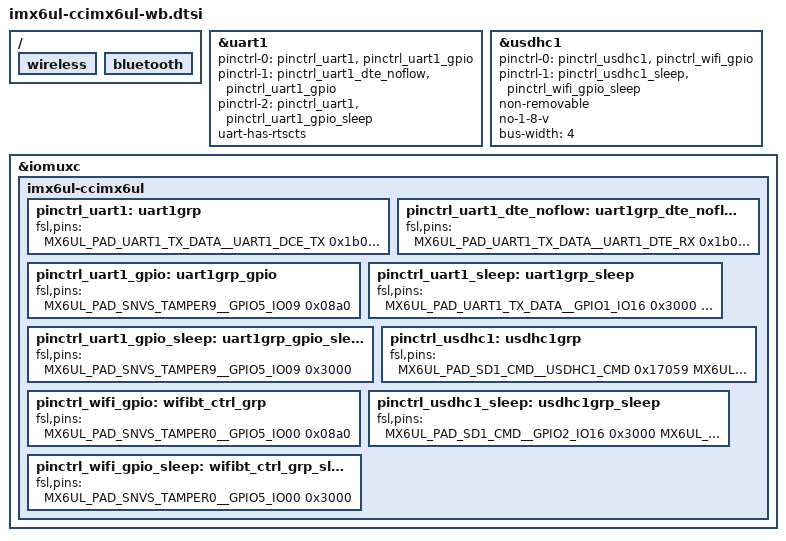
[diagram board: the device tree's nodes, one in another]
/*
 * Copyright 2016, 2017 Digi International, Inc.
 *
 * The code contained herein is licensed under the GNU General Public
 * License. You may obtain a copy of the GNU General Public License
 * Version 2 or later at the following locations:
 *
 * http://www.opensource.org/licenses/gpl-license.html
 * http://www.gnu.org/copyleft/gpl.html
 */

/* ConnectCore 6UL (common) */
#include "imx6ul-ccimx6ul.dtsi"

/ {
	wireless {
		/* U-Boot will fill in the MAC address here */
	};

	bluetooth {
		/* U-Boot will fill in the MAC address here */
	};
};

/* UART1 (Bluetooth) */
&uart1 {
	pinctrl-names = "default", "dte_noflow", "sleep";
	pinctrl-0 = <&pinctrl_uart1 &pinctrl_uart1_gpio>;
	pinctrl-1 = <&pinctrl_uart1_dte_noflow &pinctrl_uart1_gpio>;
	pinctrl-2 = <&pinctrl_uart1 &pinctrl_uart1_gpio_sleep>;
	uart-has-rtscts;
	/*
	 * NOTE: The default configuration for CC6UL SOM hardware vesion 4
	 * onwards is:
	 *	- pinctrl-0
	 *	- HW flow control enabled (uart-has-rtscts)
	 *	- DCE mode (default)
	 * For SOMs with hardware version < 4 the UART driver changes the
	 * configuration of UART1 to:
	 *	- pinctrl-1
	 *	- no HW flow control
	 *	- DTE mode
	 */
	status = "okay";
};

/* USDHC1 (Wireless) */
&usdhc1 {
	pinctrl-names = "default", "sleep";
	pinctrl-0 = <&pinctrl_usdhc1 &pinctrl_wifi_gpio>;
	pinctrl-1 = <&pinctrl_usdhc1_sleep &pinctrl_wifi_gpio_sleep>;
	non-removable;
	no-1-8-v;
	bus-width = <4>;
	status = "okay";
};

&iomuxc {
	imx6ul-ccimx6ul {
		/* This iomux (pinctrl_uart1) does not work for SOM v3 or older */
		pinctrl_uart1: uart1grp {
			fsl,pins = <
				MX6UL_PAD_UART1_TX_DATA__UART1_DCE_TX	0x1b0b1
				MX6UL_PAD_UART1_RX_DATA__UART1_DCE_RX	0x1b0b1
				MX6UL_PAD_UART1_RTS_B__UART1_DCE_RTS	0x1b0b1
				MX6UL_PAD_UART1_CTS_B__UART1_DCE_CTS	0x1b0b1
			>;
		};

		pinctrl_uart1_dte_noflow: uart1grp_dte_noflow {
			fsl,pins = <
				MX6UL_PAD_UART1_TX_DATA__UART1_DTE_RX	0x1b0b1
				MX6UL_PAD_UART1_RX_DATA__UART1_DTE_TX	0x1b0b1
				MX6UL_PAD_UART1_RTS_B__GPIO1_IO19	0x1b0b1
				MX6UL_PAD_UART1_CTS_B__GPIO1_IO18	0x1b0b1
			>;
		};

		pinctrl_uart1_gpio: uart1grp_gpio {
			fsl,pins = <
				/* BT_EN. Configure as open-drain */
				MX6UL_PAD_SNVS_TAMPER9__GPIO5_IO09	0x08a0
			>;
		};

		pinctrl_uart1_sleep: uart1grp_sleep {
			fsl,pins = <
				MX6UL_PAD_UART1_TX_DATA__GPIO1_IO16	0x3000
				MX6UL_PAD_UART1_RX_DATA__GPIO1_IO17	0x3000
				MX6UL_PAD_UART1_RTS_B__GPIO1_IO19	0x3000
				MX6UL_PAD_UART1_CTS_B__GPIO1_IO18	0x3000
			>;
		};

		pinctrl_uart1_gpio_sleep: uart1grp_gpio_sleep {
			fsl,pins = <
				/* BT_EN */
				MX6UL_PAD_SNVS_TAMPER9__GPIO5_IO09	0x3000
			>;
		};

		pinctrl_usdhc1: usdhc1grp {
			fsl,pins = <
				MX6UL_PAD_SD1_CMD__USDHC1_CMD		0x17059
				MX6UL_PAD_SD1_CLK__USDHC1_CLK		0x17051
				MX6UL_PAD_SD1_DATA0__USDHC1_DATA0	0x17059
				MX6UL_PAD_SD1_DATA1__USDHC1_DATA1	0x17059
				MX6UL_PAD_SD1_DATA2__USDHC1_DATA2	0x17059
				MX6UL_PAD_SD1_DATA3__USDHC1_DATA3	0x17059
			>;
		};

		pinctrl_wifi_gpio: wifibt_ctrl_grp {
			fsl,pins = <
				/* WL_EN. Configure as open-drain */
				MX6UL_PAD_SNVS_TAMPER0__GPIO5_IO00	0x08a0
			>;
		};

		pinctrl_usdhc1_sleep: usdhc1grp_sleep {
			fsl,pins = <
				MX6UL_PAD_SD1_CMD__GPIO2_IO16		0x3000
				MX6UL_PAD_SD1_CLK__GPIO2_IO17		0x3000
				MX6UL_PAD_SD1_DATA0__GPIO2_IO18		0x3000
				MX6UL_PAD_SD1_DATA1__GPIO2_IO19		0x3000
				MX6UL_PAD_SD1_DATA2__GPIO2_IO20		0x3000
				MX6UL_PAD_SD1_DATA3__GPIO2_IO21		0x3000
			>;
		};

		pinctrl_wifi_gpio_sleep: wifibt_ctrl_grp_sleep {
			fsl,pins = <
				MX6UL_PAD_SNVS_TAMPER0__GPIO5_IO00	0x3000
			>;
		};
	};
};
